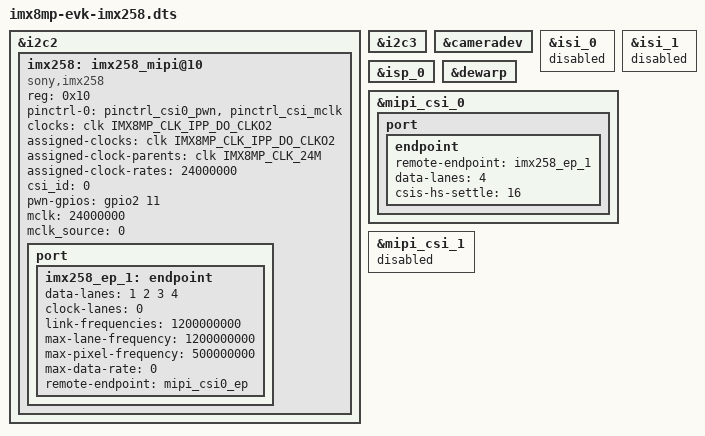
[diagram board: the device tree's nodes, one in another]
 /*
  * Copyright 2022-2025 NXP
  * SPDX-License-Identifier: (GPL-2.0-only OR MIT)
  */

/dts-v1/;

#include "imx8mp-evk.dts"

&i2c2 {
	/delete-node/ov5640_mipi@3c;

	imx258: imx258_mipi@10 {
		compatible = "sony,imx258";
		reg = <0x10>;
		pinctrl-names = "default";
		pinctrl-0 = <&pinctrl_csi0_pwn>, <&pinctrl_csi_mclk>;
		clocks = <&clk IMX8MP_CLK_IPP_DO_CLKO2>;
		clock-names = "csi_mclk";
		assigned-clocks = <&clk IMX8MP_CLK_IPP_DO_CLKO2>;
		assigned-clock-parents = <&clk IMX8MP_CLK_24M>;
		assigned-clock-rates = <24000000>;
		csi_id = <0>;
		pwn-gpios = <&gpio2 11 GPIO_ACTIVE_HIGH>;
		mclk = <24000000>;
		mclk_source = <0>;
		status = "okay";

		port {
			imx258_ep_1: endpoint {
				data-lanes = <1 2 3 4>;
				clock-lanes = <0>;
				link-frequencies = /bits/ 64 <1200000000>;

				max-lane-frequency = /bits/ 64 <1200000000>;
				max-pixel-frequency = /bits/ 64 <500000000>;
				max-data-rate = /bits/ 64 <0>;

				remote-endpoint = <&mipi_csi0_ep>;
			};
		};
	};
	
};

&i2c3 {
	/delete-node/ov5640_mipi@3c;

};

&cameradev {
	status = "okay";
};

&isi_0 {
	status = "disabled";
};

&isi_1 {
	status = "disabled";
};

&isp_0 {
	status = "okay";
};

&dewarp {
	status = "okay";
};

&mipi_csi_0 {
	status = "okay";

	port {
		 endpoint {
			remote-endpoint = <&imx258_ep_1>;
			data-lanes = <4>;
			csis-hs-settle = <16>;
		};
	};
};

&mipi_csi_1 {
	status = "disabled";
	/delete-property/ #address-cells;
	/delete-property/ #size-cells;
	/delete-node/port@1;
};
